# MESSIBLE register map
Vendor: litex
Registers are 8-bit, read-write, reset 0x0 unless marked. A register's access mark holds for its fields unless they carry their own. Offsets are from the block's base; [hi:lo] are bit positions.

## USB
Base 0xE0004800
0x00 PULLUP_OUT — GPIO Output(s) Control.
  [0] pullup_out
0x04 ADDRESS — Sets the USB device address, in order to ignore packets going to other devices on the bus. This value is reset when the host issues a USB Device Reset condition.
  [6:0] addr — Write the USB address from USB ``SET_ADDRESS`` packets.
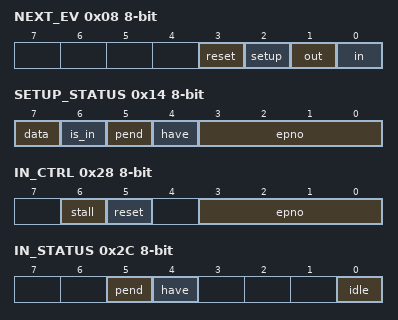
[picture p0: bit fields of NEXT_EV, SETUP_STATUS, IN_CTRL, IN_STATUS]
0x08 NEXT_EV ro — In ``eptri``, there are three endpoints. It is possible for an IRQ to fire and have all three bits set. Under these circumstances it can be difficult to know which event to process first. Use this register to determine which event needs to be processed first. Only one bit will ever be set at a time.
  [3] reset — ``1`` if the next event is a ``RESET`` event
  [2] setup — ``1`` if the next event is an ``SETUP`` event
  [1] out — ``1`` if the next event is an ``OUT`` event
  [0] in — ``1`` if the next event is an ``IN`` event
0x0C SETUP_DATA ro — Data from the last ``SETUP`` transactions. It will be 10 bytes long, because it will include the CRC16. This is a FIFO, and the queue is advanced automatically.
  [7:0] data — The next byte of ``SETUP`` data
0x10 SETUP_CTRL — Controls for managing how to handle ``SETUP`` transactions.
  [5] reset — Write a ``1`` here to reset the `SETUP` handler.
0x14 SETUP_STATUS ro — Status about the most recent ``SETUP`` transactions, and the state of the FIFO.
  [7] data — ``1`` if a DATA stage is expected.
  [6] is_in — ``1`` if an IN stage was detected.
  [5] pend — ``1`` if there is an IRQ pending.
  [4] have — ``1`` if there is data in the FIFO.
  [3:0] epno — The destination endpoint for the most recent SETUP token.
0x18 SETUP_EV_STATUS
  [1:0] setup_ev_status
0x1C SETUP_EV_PENDING
  [1:0] setup_ev_pending
0x20 SETUP_EV_ENABLE
  [1:0] setup_ev_enable
0x24 IN_DATA — Each byte written into this register gets added to an outgoing FIFO. Any bytes that are written here will be transmitted in the order in which they were added. The FIFO queue is automatically advanced with each write. The FIFO queue is 64 bytes deep. If you exceed this amount, the result is undefined.
  [7:0] data — The next byte to add to the queue.
0x28 IN_CTRL — Enables transmission of data in response to ``IN`` tokens, or resets the contents of the FIFO.
  [6] stall — Write a ``1`` here to stall the EP written in ``EP``.
  [5] reset — Write a ``1`` here to clear the contents of the FIFO.
  [3:0] epno — The endpoint number for the transaction that is queued in the FIFO.
0x2C IN_STATUS ro — Status about the IN handler. As soon as you write to `IN_DATA`, ``IN_STATUS.HAVE`` should go to ``1``.
  [5] pend — ``1`` if there is an IRQ pending.
  [4] have — This value is ``0`` if the FIFO is empty.
  [0] idle — This value is ``1`` if the packet has finished transmitting.
0x30 IN_EV_STATUS
  [0] in_ev_status
0x34 IN_EV_PENDING
  [0] in_ev_pending
0x38 IN_EV_ENABLE
  [0] in_ev_enable
0x3C OUT_DATA ro — Data received from the host will go into a FIFO. This register reflects the contents of the top byte in that FIFO. Reading from this register advances the FIFO pointer.
  [7:0] data — The top byte of the receive FIFO.
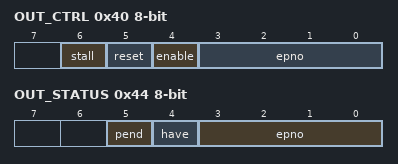
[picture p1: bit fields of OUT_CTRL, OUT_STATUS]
0x40 OUT_CTRL — Controls for receiving packet data. To enable an endpoint, write its value to ``epno``, with the ``enable`` bit set to ``1`` to enable an endpoint, or ``0`` to disable it. Resetting the OutHandler will set all ``enable`` bits to 0. Similarly, you can adjust the ``STALL`` state by setting or clearing the ``stall`` bit.
  [6] stall — Write a ``1`` here to stall an endpoint
  [5] reset — Write a ``1`` here to reset the ``OUT`` handler
  [4] enable — Write a ``1`` here to enable receiving data
  [3:0] epno — The endpoint number to update the ``enable`` and ``status`` bits for.
0x44 OUT_STATUS ro — Status about the current state of the `OUT` endpoint.
  [5] pend — ``1`` if there is an IRQ pending.
  [4] have — ``1`` if there is data in the FIFO.
  [3:0] epno — The destination endpoint for the most recent ``OUT`` packet.
0x48 OUT_EV_STATUS
  [0] out_ev_status
0x4C OUT_EV_PENDING
  [0] out_ev_pending
0x50 OUT_EV_ENABLE
  [0] out_ev_enable
